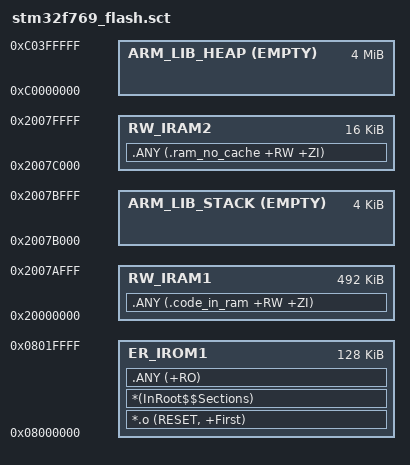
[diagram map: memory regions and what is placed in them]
;********************************************************************
;* STM32F769 linker scatter file (running code from internal FLASH) *
;********************************************************************

LR_IROM1 0x08000000 0x20000
{
   ER_IROM1 0x08000000 0x20000
   {
      *.o (RESET, +First)
      *(InRoot$$Sections)
      .ANY (+RO)
   }
   
   RW_IRAM1 0x20000000 0x7B000
   { 
      .ANY (.code_in_ram +RW +ZI)
   }
   
   ARM_LIB_STACK 0x2007C000 EMPTY -0x1000
   {
   }
   
   RW_IRAM2 0x2007C000 0x4000
   {
      .ANY (.ram_no_cache +RW +ZI)
   }
   
   ARM_LIB_HEAP 0xC0000000 EMPTY 0x400000
   {
   }
}
